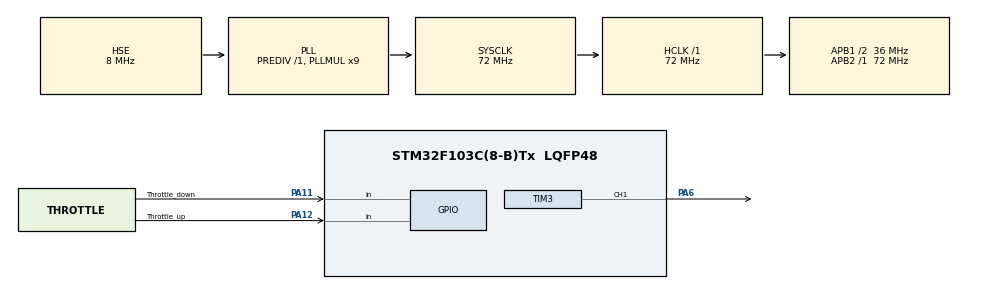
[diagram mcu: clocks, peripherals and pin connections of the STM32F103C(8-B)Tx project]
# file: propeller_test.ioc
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Mcu.Family=STM32F1
Mcu.Name=STM32F103C(8-B)Tx
Mcu.Package=LQFP48
NVIC.PriorityGroup=NVIC_PRIORITYGROUP_4
PA11.GPIO_Label=Throttle_down
PA11.GPIO_PuPd=GPIO_PULLUP
PA11.Signal=GPIO_Input
PA12.GPIO_Label=Throttle_up
PA12.GPIO_PuPd=GPIO_PULLUP
PA12.Signal=GPIO_Input
PA13.Mode=Serial_Wire
PA13.Signal=SYS_JTMS-SWDIO
PA14.Mode=Serial_Wire
PA14.Signal=SYS_JTCK-SWCLK
PA6.Signal=S_TIM3_CH1
PD0-OSC_IN.Mode=HSE-External-Oscillator
PD0-OSC_IN.Signal=RCC_OSC_IN
PD1-OSC_OUT.Mode=HSE-External-Oscillator
PD1-OSC_OUT.Signal=RCC_OSC_OUT
ProjectManager.HeapSize=0x200
ProjectManager.StackSize=0x400
ProjectManager.TargetToolchain=STM32CubeIDE
RCC.AHBFreq_Value=72000000
RCC.APB1CLKDivider=RCC_HCLK_DIV2
RCC.APB1Freq_Value=36000000
RCC.APB1TimFreq_Value=72000000
RCC.APB2Freq_Value=72000000
RCC.APB2TimFreq_Value=72000000
RCC.HCLKFreq_Value=72000000
RCC.PLLMUL=RCC_PLL_MUL9
RCC.PLLSourceVirtual=RCC_PLLSOURCE_HSE
RCC.SYSCLKFreq_VALUE=72000000
RCC.SYSCLKSource=RCC_SYSCLKSOURCE_PLLCLK
RCC.USBFreq_Value=72000000
SH.S_TIM3_CH1.0=TIM3_CH1,PWM Generation1 CH1
TIM3.Channel-PWM\ Generation1\ CH1=TIM_CHANNEL_1
TIM3.Period=20000-1
TIM3.Prescaler=72-1
VP_TIM3_VS_ClockSourceINT.Mode=Internal
board=custom

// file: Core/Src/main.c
/* USER CODE BEGIN Header */
/**
  ******************************************************************************
  * @file           : main.c
  * @brief          : Main program body
  ******************************************************************************
  * @attention
  *
  * Copyright (c) 2025 STMicroelectronics.
  * All rights reserved.
  *
  * This software is licensed under terms that can be found in the LICENSE file
  * in the root directory of this software component.
  * If no LICENSE file comes with this software, it is provided AS-IS.
  *
  ******************************************************************************
  */
/* USER CODE END Header */
#include "main.h"

/* USER CODE BEGIN Includes */
// 油門檔位對應的 PWM duty (以 TIM3 1MHz 為例)
uint16_t throttle_pwm_values[] = {1000, 1120, 1240, 1360, 1480, 1540, 1600};
uint8_t throttle_level = 0; // 對應 throttle_pwm_values[throttle_level]

// 紀錄按鍵狀態（防止長按觸發多次）
uint8_t last_up_state = 1;
uint8_t last_down_state = 1;
/* USER CODE END Includes */

TIM_HandleTypeDef htim3;

void SystemClock_Config(void);
static void MX_GPIO_Init(void);
static void MX_TIM3_Init(void);

int main(void)
{

  /* MCU Configuration--------------------------------------------------------*/

  /* Reset of all peripherals, Initializes the Flash interface and the Systick. */
  HAL_Init();

  /* Configure the system clock */
  SystemClock_Config();

  /* Initialize all configured peripherals */
  MX_GPIO_Init();
  MX_TIM3_Init();
  /* USER CODE BEGIN 2 */
  HAL_TIM_PWM_Start(&htim3, TIM_CHANNEL_1);
  __HAL_TIM_SET_COMPARE(&htim3, TIM_CHANNEL_1, throttle_pwm_values[throttle_level]);
  /* USER CODE END 2 */
  void set_pwm_us(uint16_t us) {
      // 假設 timer 預設為 1us per tick，Period = 20000
      __HAL_TIM_SET_COMPARE(&htim3, TIM_CHANNEL_1, us);
  }
  void esc_calibration_sequence(void) {
      // 啟動PWM
      HAL_TIM_PWM_Start(&htim3, TIM_CHANNEL_1);

      // 步驟1: 傳送最大油門
      set_pwm_us(2000);
      HAL_Delay(3000); // 等ESC發出提示音

      // 步驟2: 傳送最小油門
      set_pwm_us(1000);
      HAL_Delay(3000); // 等ESC完成校正啟動

      // 校正完成後保留最小油門
  }
  /* Infinite loop */
  while (1)
  {
	  read_buttons_and_update_throttle();
	  HAL_Delay(10);
  }
}

void update_pwm() {
    __HAL_TIM_SET_COMPARE(&htim3, TIM_CHANNEL_1, throttle_pwm_values[throttle_level]);
}
void read_buttons_and_update_throttle() {
    // 讀取按鍵
    uint8_t up_now = HAL_GPIO_ReadPin(GPIOA, GPIO_PIN_12);
    uint8_t down_now = HAL_GPIO_ReadPin(GPIOA, GPIO_PIN_11);

    // === 按鍵上升邊緣偵測 ===

    if (up_now == GPIO_PIN_RESET && last_up_state == GPIO_PIN_SET) {
        HAL_Delay(50); // debounce
        if (HAL_GPIO_ReadPin(GPIOA, GPIO_PIN_12) == GPIO_PIN_RESET) {
            if (throttle_level < 6) {
                throttle_level++;
                update_pwm();
            }
        }
    }

    if (down_now == GPIO_PIN_RESET && last_down_state == GPIO_PIN_SET) {
        HAL_Delay(50); // debounce
        if (HAL_GPIO_ReadPin(GPIOA, GPIO_PIN_11) == GPIO_PIN_RESET) {
            if (throttle_level > 0) {
                throttle_level--;
                update_pwm();
            }
        }
    }

    // 記錄上次狀態
    last_up_state = up_now;
    last_down_state = down_now;
}
void SystemClock_Config(void)
{
  RCC_OscInitTypeDef RCC_OscInitStruct = {0};
  RCC_ClkInitTypeDef RCC_ClkInitStruct = {0};

  /** Initializes the RCC Oscillators according to the specified parameters
  * in the RCC_OscInitTypeDef structure.
  */
  RCC_OscInitStruct.OscillatorType = RCC_OSCILLATORTYPE_HSE;
  RCC_OscInitStruct.HSEState = RCC_HSE_ON;
  RCC_OscInitStruct.HSEPredivValue = RCC_HSE_PREDIV_DIV1;
  RCC_OscInitStruct.HSIState = RCC_HSI_ON;
  RCC_OscInitStruct.PLL.PLLState = RCC_PLL_ON;
  RCC_OscInitStruct.PLL.PLLSource = RCC_PLLSOURCE_HSE;
  RCC_OscInitStruct.PLL.PLLMUL = RCC_PLL_MUL9;
  if (HAL_RCC_OscConfig(&RCC_OscInitStruct) != HAL_OK)
  {
    Error_Handler();
  }

  /** Initializes the CPU, AHB and APB buses clocks
  */
  RCC_ClkInitStruct.ClockType = RCC_CLOCKTYPE_HCLK|RCC_CLOCKTYPE_SYSCLK
                              |RCC_CLOCKTYPE_PCLK1|RCC_CLOCKTYPE_PCLK2;
  RCC_ClkInitStruct.SYSCLKSource = RCC_SYSCLKSOURCE_PLLCLK;
  RCC_ClkInitStruct.AHBCLKDivider = RCC_SYSCLK_DIV1;
  RCC_ClkInitStruct.APB1CLKDivider = RCC_HCLK_DIV2;
  RCC_ClkInitStruct.APB2CLKDivider = RCC_HCLK_DIV1;

  if (HAL_RCC_ClockConfig(&RCC_ClkInitStruct, FLASH_LATENCY_2) != HAL_OK)
  {
    Error_Handler();
  }
}

static void MX_TIM3_Init(void)
{

  TIM_ClockConfigTypeDef sClockSourceConfig = {0};
  TIM_MasterConfigTypeDef sMasterConfig = {0};
  TIM_OC_InitTypeDef sConfigOC = {0};

  htim3.Instance = TIM3;
  htim3.Init.Prescaler = 72-1;
  htim3.Init.CounterMode = TIM_COUNTERMODE_UP;
  htim3.Init.Period = 20000-1;
  htim3.Init.ClockDivision = TIM_CLOCKDIVISION_DIV1;
  htim3.Init.AutoReloadPreload = TIM_AUTORELOAD_PRELOAD_DISABLE;
  if (HAL_TIM_Base_Init(&htim3) != HAL_OK)
  {
    Error_Handler();
  }
  sClockSourceConfig.ClockSource = TIM_CLOCKSOURCE_INTERNAL;
  if (HAL_TIM_ConfigClockSource(&htim3, &sClockSourceConfig) != HAL_OK)
  {
    Error_Handler();
  }
  if (HAL_TIM_PWM_Init(&htim3) != HAL_OK)
  {
    Error_Handler();
  }
  sMasterConfig.MasterOutputTrigger = TIM_TRGO_RESET;
  sMasterConfig.MasterSlaveMode = TIM_MASTERSLAVEMODE_DISABLE;
  if (HAL_TIMEx_MasterConfigSynchronization(&htim3, &sMasterConfig) != HAL_OK)
  {
    Error_Handler();
  }
  sConfigOC.OCMode = TIM_OCMODE_PWM1;
  sConfigOC.Pulse = 0;
  sConfigOC.OCPolarity = TIM_OCPOLARITY_HIGH;
  sConfigOC.OCFastMode = TIM_OCFAST_DISABLE;
  if (HAL_TIM_PWM_ConfigChannel(&htim3, &sConfigOC, TIM_CHANNEL_1) != HAL_OK)
  {
    Error_Handler();
  }
  HAL_TIM_MspPostInit(&htim3);

}

static void MX_GPIO_Init(void)
{
  GPIO_InitTypeDef GPIO_InitStruct = {0};

  /* GPIO Ports Clock Enable */
  __HAL_RCC_GPIOD_CLK_ENABLE();
  __HAL_RCC_GPIOA_CLK_ENABLE();

  /*Configure GPIO pins : Throttle_down_Pin Throttle_up_Pin */
  GPIO_InitStruct.Pin = Throttle_down_Pin|Throttle_up_Pin;
  GPIO_InitStruct.Mode = GPIO_MODE_INPUT;
  GPIO_InitStruct.Pull = GPIO_PULLUP;
  HAL_GPIO_Init(GPIOA, &GPIO_InitStruct);

}

void Error_Handler(void)
{
  __disable_irq();
  while (1)
  {
  }
}
